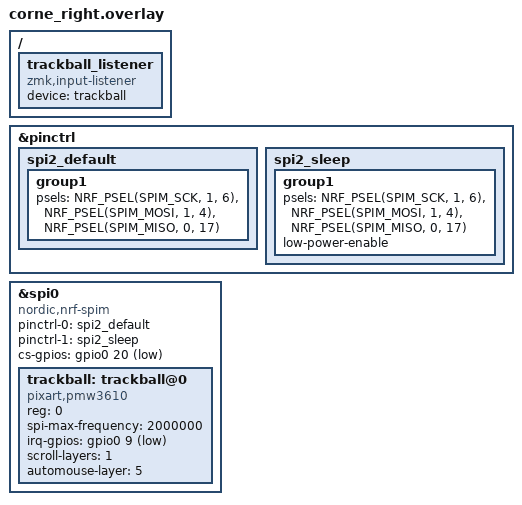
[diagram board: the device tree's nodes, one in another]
&pinctrl {
    spi2_default: spi2_default {
        group1 {
            psels = <NRF_PSEL(SPIM_SCK, 1, 6)>,
                <NRF_PSEL(SPIM_MOSI, 1, 4)>,
                <NRF_PSEL(SPIM_MISO, 0, 17)>;
        };
    };

    spi2_sleep: spi2_sleep {
        group1 {
            psels = <NRF_PSEL(SPIM_SCK, 1, 6)>,
                <NRF_PSEL(SPIM_MOSI, 1, 4)>,
                <NRF_PSEL(SPIM_MISO, 0, 17)>;
            low-power-enable;
        };
    };
};

&spi0 {
    status = "okay";
    compatible = "nordic,nrf-spim";
    pinctrl-0 = <&spi2_default>;
    pinctrl-1 = <&spi2_sleep>;
    pinctrl-names = "default", "sleep";
    cs-gpios = <&gpio0 20 GPIO_ACTIVE_LOW>;

    trackball: trackball@0 {
        status = "okay";
        compatible = "pixart,pmw3610";
        reg = <0>;
        spi-max-frequency = <2000000>;
        irq-gpios = <&gpio0 9 (GPIO_ACTIVE_LOW | GPIO_PULL_UP)>;
        scroll-layers = <1>;
        // snipe-layers = <>;
        automouse-layer = <5>;
    };
};

/ {
    trackball_listener {
        compatible = "zmk,input-listener";
        device = <&trackball>;
    };
};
